# R7FA6M3AH register map
Vendor: Renesas; Series: RA6; File version: 1.2
CPU: CM4 r0p1, little endian, MPU, FPU, VTOR, 4 interrupt priority bits
Registers are 32-bit, read-write, reset 0x0 unless marked. A register's access mark holds for its fields unless they carry their own. Offsets are from the block's base; [hi:lo] are bit positions; {n}, {i} and the like mark numbered series; <NAME> marks a mode.

## FCACHE — Flash Cache
Base 0x4001C000
0x100 FCACHEE 16-bit — Flash Cache Enable Register
  [0] FCACHEEN — FCACHE Enable
    0=FCACHE is disabled; 1=FCACHE is enabled
0x104 FCACHEIV 16-bit — Flash Cache Invalidate Register
  [0] FCACHEIV write-1-sets read-modifies — FCACHE Invalidation
    0=(Read)not in progress / (Write) no effect; 1=(Read)in progress /(Write) Starting Cache Invalidation
0x11C FLWT 8-bit — Flash Wait Cycle Register
  [2:0] FLWT — Flash Wait Cycle
    0=0 wait (ICLK<=80MHz); 1=1 wait (80MHz < ICLK <=160MHz); 2=2 waits (160MHz < ICLK <=240MHz); other=others (Setting prohibited)

## DAC12 — 12-bit D/A converter
Base 0x4005E000
{0x0+2i} DADR{i} (i=0..1) 16-bit — D/A Data Register {i}
  [15:0] DADR — D/A Data RegisterNOTE: When DADPR.DPSEL = 0, the high-order 4 bits are fixed to 0: right justified format. When DADPR.DPSEL = 1, the low-order 4 bits are fixed to 0: left justified format.
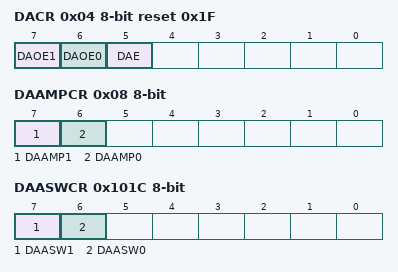
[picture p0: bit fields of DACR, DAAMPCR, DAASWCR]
0x04 DACR 8-bit reset 0x1F — D/A Control Register
  [7] DAOE1 — D/A Output Enable 1
    0=Analog output of channel 1 (DA1) is disabled; 1=D/A conversion of channel 1 is enabled. Analog output of channel 1 (DA1) is enabled.
  [6] DAOE0 — D/A Output Enable 0
    0=Analog output of channel 0 (DA0) is disabled; 1=D/A conversion of channel 0 is enabled. Analog output of channel 0 (DA0) is enabled.
  [5] DAE — D/A Enable
    0=D/A conversion is independently controlled on channels 0 and 1; 1=D/A conversion on channels 0 and 1 is controlled as a single whole
0x05 DADPR 8-bit — DADRm Format Select Register
  [7] DPSEL — DADRm Format Select
    0=Right justified format; 1=Left justified format
0x06 DAADSCR 8-bit — D/A-A/D Synchronous Start Control Register
  [7] DAADST — D/A-A/D Synchronous Conversion
    0=D/A converter operation does not synchronize with A/D converter operation (unit 1) (countermeasure against interference between D/A and A/D conversions is disabled); 1=D/A converter operation synchronizes with A/D converter operation (unit 1) (countermeasure against interference between D/A and A/D conversions is enabled)
0x08 DAAMPCR 8-bit — D/A Output Amplifier Control Register
  [7] DAAMP1 — Amplifier Control 1
    0=Output amplifier of channel 1 is not used; 1=Output amplifier of channel 1 is used
  [6] DAAMP0 — Amplifier Control 0
    0=Output amplifier of channel 0 is not used; 1=Output amplifier of channel 0 is used
0x101C DAASWCR 8-bit — D/A Amplifier Stabilization Wait Control Register
  [7] DAASW1 — D/A Amplifier Stabilization Wait 1
    0=Amplifier stabilization wait off (output) for channel 1; 1=Amplifier stabilization wait on (high-Z) for channel 1
  [6] DAASW0 — D/A Amplifier Stabilization Wait 0
    0=Amplifier stabilization wait off (output) for channel 0; 1=Amplifier stabilization wait on (high-Z) for channel 0

## AMI — ADC-DAC Interface
Base 0x4005F000
0xC0 DAADUSR 8-bit — D/A A/D Synchronous Unit Select Register
  [1] AMADSEL1 — A/D Unit 1 Select
    0=Unit 1 is not selected; 1=Unit 1 is selected

## POEG — Port Output Enable Module for GPT
Base 0x40042000
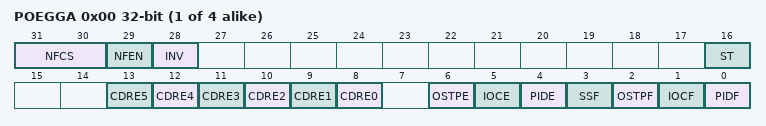
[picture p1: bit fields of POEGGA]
0x00 POEGG{x} (x=A,B,C,D; step 0x100) — POEG Group {x} Setting Register
  [31:30] NFCS — Noise Filter Clock Select
    0=Sampling GTETRG pin input level for three times in every PCLKB; 1=Sampling GTETRG pin input level for three times in every PCLKB /8; 2=Sampling GTETRG pin input level for three times in every PCLKB /32; 3=Sampling GTETRG pin input level for three times in every PCLKB /128
  [29] NFEN — Noise Filter Enable
    0=Filtering noise disabled; 1=Filtering noise enabled
  [28] INV — GTETRG Input Reverse
    0=GTETRG Input; 1=GTETRG Input Reversed
  [16] ST ro — GTETRG Input Status Flag
    0=GTETRG input after filtering is 0; 1=GTETRG input after filtering is 1
  [n+8] CDRE{n} (n=0..5) — Comparator Disable Request Enable {n}Note: Can be modified only once after a reset.
    0=A disable request of comparator {n} disabled; 1=A disable request of comparator {n} enabled
  [6] OSTPE — Oscillation Stop Detection EnableNote: Can be modified only once after a reset.
    0=A output-disable request from the oscillation stop detection disabled; 1=A output-disable request from the oscillation stop detection enabled
  [5] IOCE — Enable for GPT Output-Disable RequestNote: Can be modified only once after a reset.
    0=Disable output-disable requests from GPT disable request; 1=Enable output-disable requests from GPT disable request
  [4] PIDE — Port Input Detection EnableNote: Can be modified only once after a reset.
    0=A output-disable request from the GTETRG pins disabled; 1=A output-disable request from the GTETRG pins enabled
  [3] SSF — Software Stop Flag
    0=A output-disable request from software has not been generated; 1=A output-disable request from software has been generated
  [2] OSTPF write-0-clears read-modifies — Oscillation Stop Detection Flag
    0=A output-disable request from the oscillation stop detection has not been generated; 1=A output-disable request from the oscillation stop detection has been generated
  [1] IOCF write-0-clears read-modifies — Real Time Overcurrent Detection Flag
    0=A output-disable request from GPT disable request or comparator interrupt has not been generated; 1=A output-disable request from GPT disable request or comparator interrupt has been generated
  [0] PIDF write-0-clears read-modifies — Port Input Detection Flag
    0=A output-disable request from the GTETRG pin has not been generated; 1=A output-disable request from the GTETRG pin has been generated
